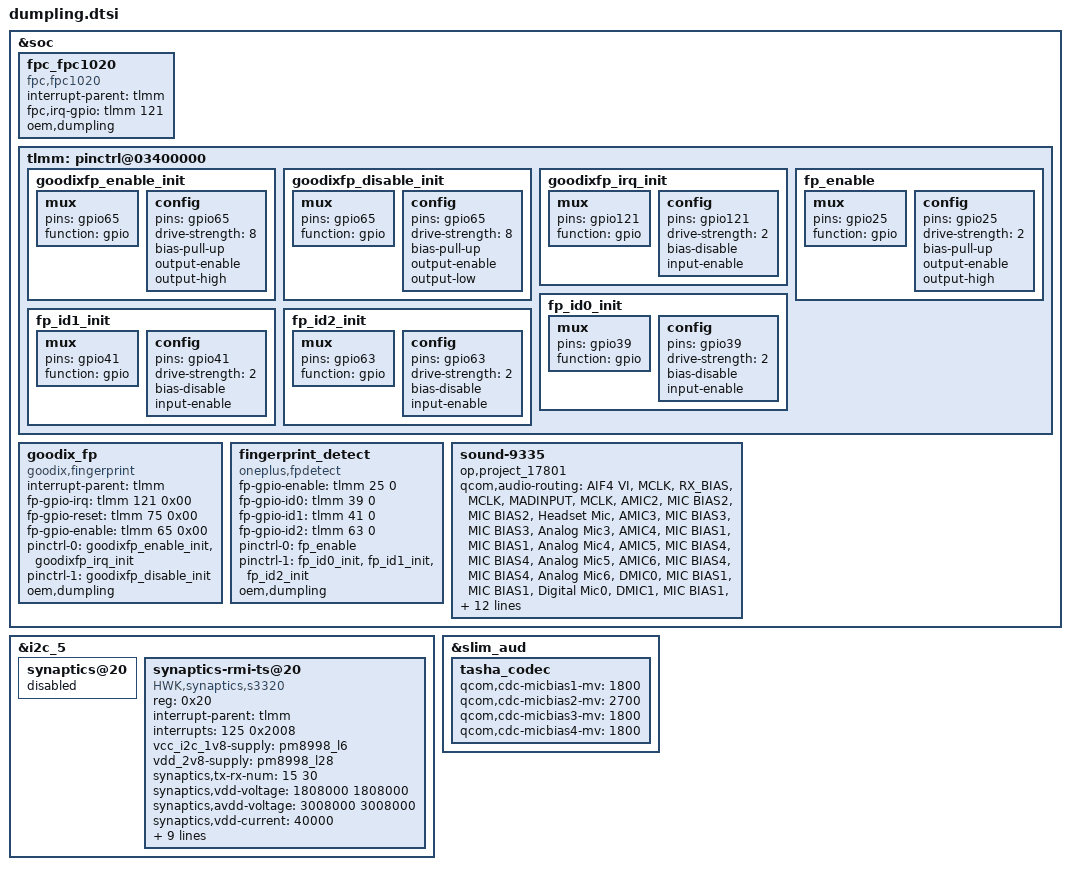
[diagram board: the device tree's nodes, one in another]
/* Copyright (c) 2016-2017, The Linux Foundation. All rights reserved.
 *
 * This program is free software; you can redistribute it and/or modify
 * it under the terms of the GNU General Public License version 2 and
 * only version 2 as published by the Free Software Foundation.
 *
 * This program is distributed in the hope that it will be useful,
 * but WITHOUT ANY WARRANTY; without even the implied warranty of
 * MERCHANTABILITY or FITNESS FOR A PARTICULAR PURPOSE.  See the
 * GNU General Public License for more details.
 */

#include "oneplus5-common.dtsi"

/* I/O */
&soc {

	/* Fingerprint */
	fpc_fpc1020 {
		compatible = "fpc,fpc1020";
		interrupt-parent = <&tlmm>;
		fpc,irq-gpio    = <&tlmm 121 0>;
		/*
		*fpc,gpio_id0    = <&tlmm 39 0>;
		*fpc,gpio_id1    = <&tlmm 41 0>;
		*fpc,gpio_id2    = <&tlmm 63 0>;
		*/
		oem,dumpling;
	};

	tlmm: pinctrl@03400000 {
		goodixfp_enable_init: goodixfp_enable_init {
			mux {
				pins = "gpio65";
				function = "gpio";
			};

			config {
				pins = "gpio65";
				drive-strength = <8>;
				bias-pull-up;
				output-enable;
				output-high;
			};
		};
		goodixfp_disable_init: goodixfp_disable_init {
			mux {
				pins = "gpio65";
				function = "gpio";
			};

			config {
				pins = "gpio65";
				drive-strength = <8>;
				bias-pull-up;
				output-enable;
				output-low;
			};
		};
		goodixfp_irq_init: goodixfp_irq_init {
			mux {
				pins = "gpio121";
				function = "gpio";
			};

			config {
				pins = "gpio121";
				drive-strength = <2>;
				bias-disable;
				input-enable;
			};
		};
	};

	goodix_fp {
		compatible = "goodix,fingerprint";
		interrupt-parent = <&tlmm>;
		fp-gpio-irq = <&tlmm 121 0x00>;
		fp-gpio-reset = <&tlmm 75 0x00>;
		fp-gpio-enable = <&tlmm 65 0x00>;
		pinctrl-names = "fp_en_init", "fp_dis_init";
		pinctrl-0 = <&goodixfp_enable_init &goodixfp_irq_init>;
		pinctrl-1 = <&goodixfp_disable_init>;
		status = "okay";
		oem,dumpling;
	};

	tlmm: pinctrl@03400000 {
		fp_enable: fp_enable {
			mux {
				pins = "gpio25";
				function = "gpio";
			};

			config {
				pins = "gpio25";
				drive-strength = <2>;
				bias-pull-up;
				output-enable;
				output-high;
			};
		};
		fp_id0_init: fp_id0_init {
			mux {
				pins = "gpio39";
				function = "gpio";
			};

			config {
				pins = "gpio39";
				drive-strength = <2>;
				bias-disable;
				input-enable;
			};
		};
		fp_id1_init: fp_id1_init {
			mux {
				pins = "gpio41";
				function = "gpio";
			};

			config {
				pins = "gpio41";
				drive-strength = <2>;
				bias-disable;
				input-enable;
			};
		};
		fp_id2_init: fp_id2_init {
			mux {
				pins = "gpio63";
				function = "gpio";
			};

			config {
				pins = "gpio63";
				drive-strength = <2>;
				bias-disable;
				input-enable;
			};
		};
	};

	fingerprint_detect {
		compatible = "oneplus,fpdetect";
		fp-gpio-enable    = <&tlmm 25 0>;
		fp-gpio-id0    = <&tlmm 39 0>;
		fp-gpio-id1    = <&tlmm 41 0>;
		fp-gpio-id2    = <&tlmm 63 0>;
		pinctrl-names = "fp_enable", "fp_id_init";
		pinctrl-0 = <&fp_enable>;
		pinctrl-1 = <&fp_id0_init &fp_id1_init &fp_id2_init>;
		oem,dumpling;
	};

};

/* Display */
&i2c_5 {
	synaptics@20 {
		status = "disabled";
	};
	synaptics-rmi-ts@20 {
		compatible = "HWK,synaptics,s3320";
		reg = <0x20>;
		interrupt-parent = <&tlmm>;
		interrupts = <125 0x2008>;
		vcc_i2c_1v8-supply = <&pm8998_l6>;
		vdd_2v8-supply = <&pm8998_l28>;
		synaptics,tx-rx-num = <15 30>;
		synaptics,vdd-voltage = <1808000 1808000>;
		synaptics,avdd-voltage = <3008000 3008000>;
		synaptics,vdd-current = <40000>;
		synaptics,avdd-current = <20000>;
		synaptics,display-coords = <1080 2160>;
		synaptics,panel-coords = <1080 2160>;
		synaptics,reset-gpio = <&tlmm 89 0x00>;
		synaptics,irq-gpio = <&tlmm 125 0x2008>;
		oem,support_1080x2160_tp;
		oem,support_hw_poweroff;
		pinctrl-names = "pmx_ts_active", "pmx_ts_suspend";
		pinctrl-0 = <&ts_active>;
		pinctrl-1 = <&ts_int_suspend &ts_reset_suspend>;
	};
};

&slim_aud {
	tasha_codec {
		qcom,cdc-micbias1-mv = <1800>;
		qcom,cdc-micbias2-mv = <2700>;
		qcom,cdc-micbias3-mv = <1800>;
		qcom,cdc-micbias4-mv = <1800>;
	};
};

/* Audio */
&soc {
	sound-9335 {
		op,project_17801;
		qcom,audio-routing =
			"AIF4 VI", "MCLK",
			"RX_BIAS", "MCLK",
			"MADINPUT", "MCLK",
			"AMIC2", "MIC BIAS2",
			"MIC BIAS2", "Headset Mic",
			"AMIC3", "MIC BIAS3",
			"MIC BIAS3", "Analog Mic3",
			"AMIC4", "MIC BIAS1",
			"MIC BIAS1", "Analog Mic4",
			"AMIC5", "MIC BIAS4",
			"MIC BIAS4", "Analog Mic5",
			"AMIC6", "MIC BIAS4",
			"MIC BIAS4", "Analog Mic6",
			"DMIC0", "MIC BIAS1",
			"MIC BIAS1", "Digital Mic0",
			"DMIC1", "MIC BIAS1",
			"MIC BIAS1", "Digital Mic1",
			"DMIC2", "MIC BIAS4",
			"MIC BIAS4", "Digital Mic2",
			"DMIC3", "MIC BIAS4",
			"MIC BIAS4", "Digital Mic3",
			"DMIC4", "MIC BIAS3",
			"MIC BIAS3", "Digital Mic4",
			"DMIC5", "MIC BIAS3",
			"MIC BIAS3", "Digital Mic5",
			"SpkrLeft IN", "SPK1 OUT",
			"SpkrRight IN", "SPK2 OUT";
		qcom,us-euro-gpios = <>;
		qcom,msm-mbhc-hphl-swh = <1>;
		qcom,msm-mbhc-gnd-swh = <1>;
		qcom,wsa-max-devs = <0>;
		qcom,wsa-devs = <0>;
		qcom,wsa-aux-dev-prefix = <0>;
	};
};
